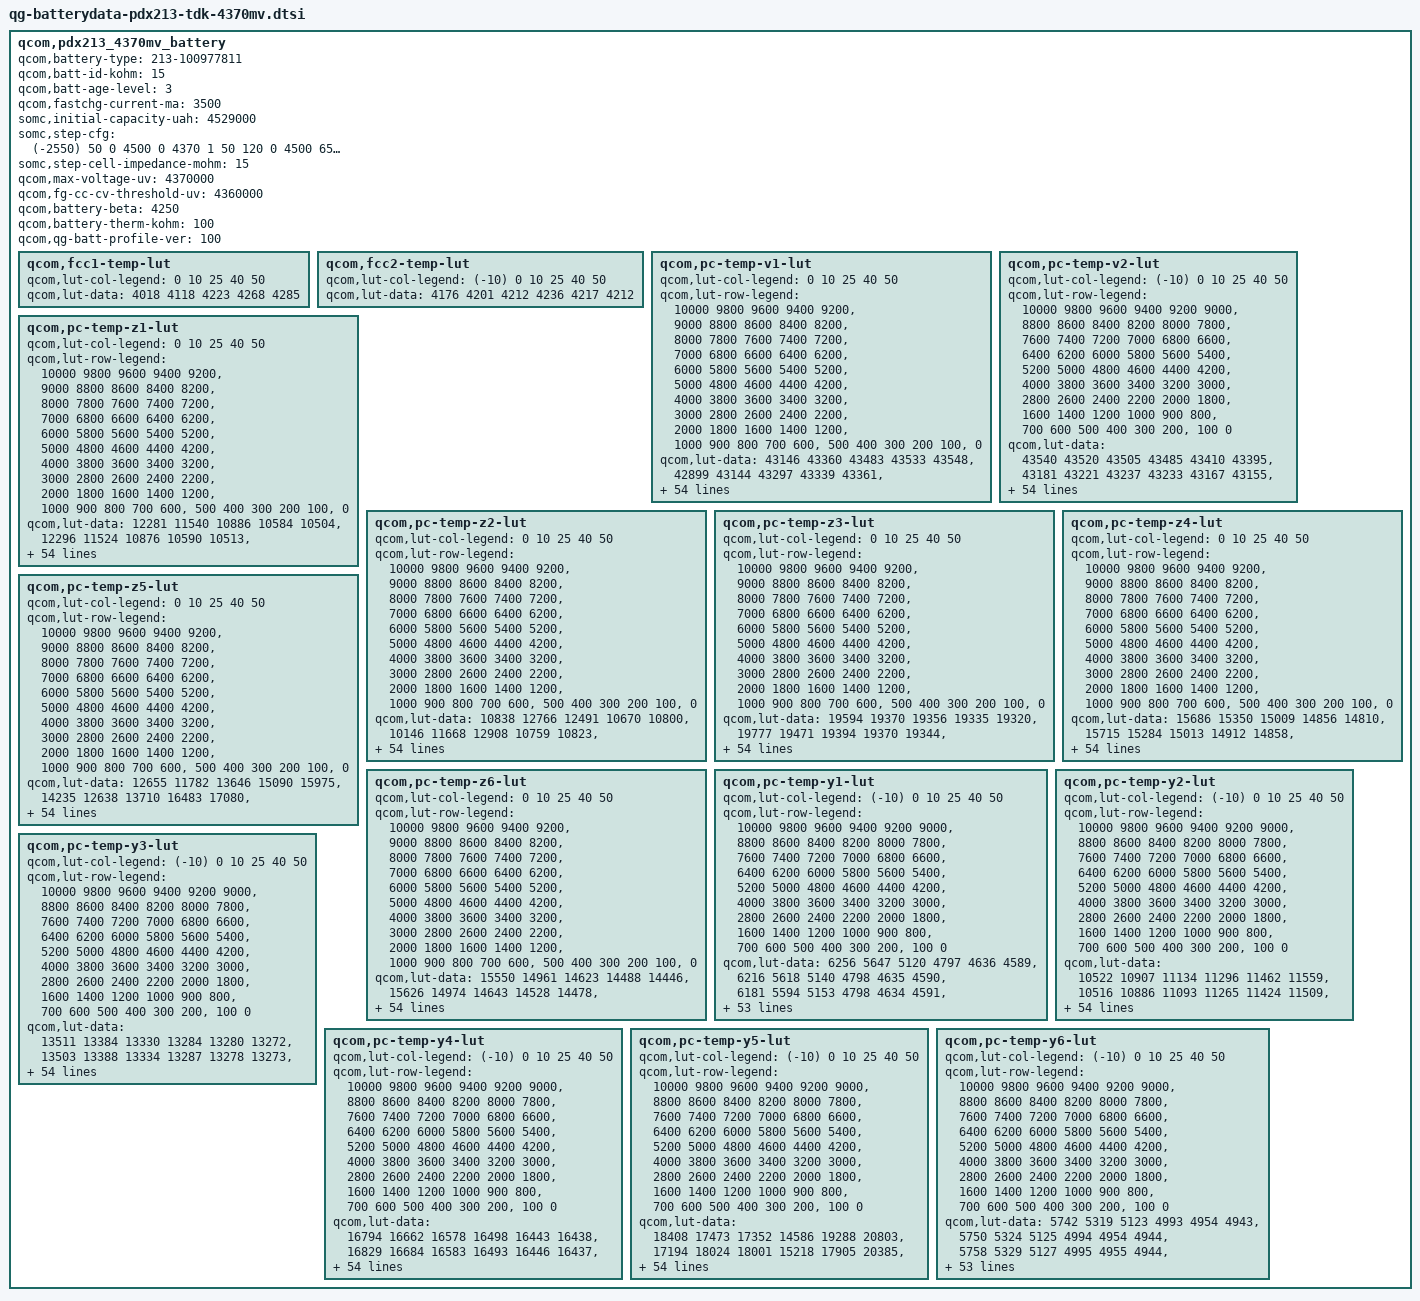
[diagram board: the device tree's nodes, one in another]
qcom,pdx213_4370mv_battery {
	/* Added or Modified by SOMC */
	qcom,battery-type = "213-100977811";
	qcom,batt-id-kohm = <15>;
	qcom,batt-age-level = <3>;
	qcom,fastchg-current-ma = <3500>;
	somc,initial-capacity-uah = <4529000>;
	somc,step-cfg = <
		(-2550) 50    0 4500    0 4370 1
		   50  120    0 4500  650 4370 2
		  120  150    0 4100 1950 4370 3
		  120  150 4100 4200 1500 4370 3
		  120  150 4200 4500  850 4370 3
		  150  200    0 4100 2150 4370 3
		  150  200 4100 4200 1750 4370 3
		  150  200 4200 4300 1500 4370 3
		  150  200 4300 4500 1050 4370 3
		  200  450    0 4150 3500 4370 3
		  200  450 4150 4200 2600 4370 3
		  200  450 4200 4300 1500 4370 3
		  200  450 4300 4500 1050 4370 3
		  450  550    0 4500 1300 4200 4
		  550 2550    0 4500    0 4200 5
	>;
	somc,step-cell-impedance-mohm = <15>;

	/* Prepared by Qualcomm */
    /* 4764144_SoMC_Licht_4221mAh_averaged_MasterSlave_Sept8th2020 */
    qcom,max-voltage-uv = <4370000>;
    qcom,fg-cc-cv-threshold-uv = <4360000>;
    /* qcom,fastchg-current-ma = <1500>; */
    /* qcom,batt-id-kohm = <0>; */
    qcom,battery-beta = <4250>;
    qcom,battery-therm-kohm = <100>;
    /* qcom,battery-type = "4764144_SoMC_Licht_4221mAh_averaged_MasterSlave_Sept8th2020"; */
    qcom,qg-batt-profile-ver = <100>;

	qcom,fcc1-temp-lut {
		qcom,lut-col-legend = <0 10 25 40 50>;
		qcom,lut-data = <4018 4118 4223 4268 4285>;
	};

	qcom,fcc2-temp-lut {
		qcom,lut-col-legend = <(-10) 0 10 25 40 50>;
		qcom,lut-data = <4176 4201 4212 4236 4217 4212>;
	};

	qcom,pc-temp-v1-lut {
		qcom,lut-col-legend = <0 10 25 40 50>;
		qcom,lut-row-legend = <10000 9800 9600 9400 9200>,
			<9000 8800 8600 8400 8200>,
			<8000 7800 7600 7400 7200>,
			<7000 6800 6600 6400 6200>,
			<6000 5800 5600 5400 5200>,
			<5000 4800 4600 4400 4200>,
			<4000 3800 3600 3400 3200>,
			<3000 2800 2600 2400 2200>,
			<2000 1800 1600 1400 1200>,
			<1000 900 800 700 600>,
			<500 400 300 200 100>,
			<0>;
		qcom,lut-data = <43146 43360 43483 43533 43548>,
			<42899 43144 43297 43339 43361>,
			<42681 42914 43072 43131 43156>,
			<42467 42674 42842 42917 42943>,
			<42248 42440 42607 42692 42724>,
			<42032 42216 42375 42459 42500>,
			<41821 41996 42153 42233 42274>,
			<41616 41782 41937 42011 42047>,
			<41416 41572 41719 41792 41823>,
			<41221 41366 41498 41573 41605>,
			<41032 41165 41281 41358 41390>,
			<40844 40968 41076 41147 41179>,
			<40657 40778 40879 40941 40971>,
			<40476 40595 40688 40743 40770>,
			<40305 40421 40503 40552 40578>,
			<40141 40262 40325 40368 40393>,
			<39991 40112 40158 40196 40218>,
			<39860 39957 39997 40034 40051>,
			<39734 39802 39834 39870 39885>,
			<39586 39633 39671 39699 39714>,
			<39416 39404 39493 39523 39540>,
			<39241 39126 39259 39322 39347>,
			<39058 38936 39017 39099 39129>,
			<38874 38836 38872 38925 38947>,
			<38748 38760 38783 38804 38816>,
			<38670 38690 38703 38702 38707>,
			<38610 38628 38615 38604 38606>,
			<38560 38566 38530 38513 38513>,
			<38517 38499 38454 38428 38427>,
			<38477 38432 38382 38349 38345>,
			<38434 38374 38319 38278 38269>,
			<38392 38323 38262 38215 38200>,
			<38353 38276 38210 38159 38138>,
			<38316 38232 38162 38105 38077>,
			<38280 38192 38120 38057 38022>,
			<38243 38152 38077 38008 37965>,
			<38206 38117 38036 37953 37898>,
			<38157 38075 37992 37894 37823>,
			<38075 38000 37926 37822 37743>,
			<37969 37890 37826 37732 37657>,
			<37855 37771 37711 37628 37560>,
			<37724 37643 37588 37509 37442>,
			<37578 37502 37450 37373 37305>,
			<37416 37338 37288 37217 37152>,
			<37286 37205 37154 37090 37029>,
			<37199 37126 37080 37019 36959>,
			<37174 37103 37060 37004 36941>,
			<37149 37084 37044 36988 36927>,
			<37120 37062 37028 36970 36912>,
			<37069 37020 36985 36922 36857>,
			<36888 36823 36756 36668 36581>,
			<36450 36393 36330 36239 36152>,
			<35886 35834 35773 35682 35596>,
			<35115 35067 35019 34928 34842>,
			<33823 33820 33856 33774 33698>,
			<30000 30000 30000 30000 30000>;
	};

	qcom,pc-temp-v2-lut {
		qcom,lut-col-legend = <(-10) 0 10 25 40 50>;
		qcom,lut-row-legend = <10000 9800 9600 9400 9200 9000>,
			<8800 8600 8400 8200 8000 7800>,
			<7600 7400 7200 7000 6800 6600>,
			<6400 6200 6000 5800 5600 5400>,
			<5200 5000 4800 4600 4400 4200>,
			<4000 3800 3600 3400 3200 3000>,
			<2800 2600 2400 2200 2000 1800>,
			<1600 1400 1200 1000 900 800>,
			<700 600 500 400 300 200>,
			<100 0>;
		qcom,lut-data = <43540 43520 43505 43485 43410 43395>,
			<43181 43221 43237 43233 43167 43155>,
			<42856 42940 42980 42989 42930 42921>,
			<42568 42681 42736 42754 42699 42691>,
			<42312 42441 42505 42527 42474 42468>,
			<42079 42208 42277 42303 42251 42246>,
			<41868 41976 42049 42077 42029 42023>,
			<41670 41746 41823 41853 41809 41802>,
			<41461 41522 41602 41632 41593 41586>,
			<41238 41299 41384 41415 41378 41373>,
			<41021 41088 41173 41203 41168 41164>,
			<40832 40904 40970 40996 40963 40960>,
			<40650 40731 40773 40795 40763 40762>,
			<40428 40548 40584 40600 40572 40570>,
			<40135 40355 40404 40410 40386 40384>,
			<39851 40154 40221 40228 40208 40204>,
			<39634 39940 40033 40060 40041 40036>,
			<39445 39718 39838 39894 39878 39874>,
			<39245 39498 39625 39711 39701 39699>,
			<39027 39273 39382 39514 39511 39515>,
			<38817 39064 39159 39311 39317 39325>,
			<38628 38884 38978 39089 39103 39114>,
			<38455 38722 38819 38878 38895 38906>,
			<38335 38577 38679 38726 38742 38753>,
			<38254 38450 38557 38610 38627 38639>,
			<38188 38329 38446 38505 38526 38538>,
			<38129 38204 38345 38406 38430 38441>,
			<38076 38086 38251 38315 38342 38350>,
			<38024 38009 38163 38230 38260 38267>,
			<37973 37958 38080 38149 38185 38190>,
			<37922 37917 38002 38077 38116 38119>,
			<37871 37880 37925 38011 38053 38055>,
			<37820 37848 37854 37952 37995 37994>,
			<37766 37815 37804 37896 37928 37922>,
			<37711 37785 37771 37845 37853 37832>,
			<37653 37750 37737 37787 37772 37736>,
			<37586 37703 37700 37714 37683 37639>,
			<37511 37639 37660 37633 37590 37539>,
			<37429 37562 37604 37555 37502 37448>,
			<37339 37465 37523 37478 37422 37368>,
			<37244 37353 37424 37390 37334 37281>,
			<37149 37224 37304 37281 37226 37172>,
			<37056 37078 37164 37154 37105 37050>,
			<36968 36934 37005 37000 36963 36909>,
			<36882 36817 36878 36908 36883 36830>,
			<36785 36740 36813 36874 36855 36804>,
			<36735 36702 36782 36858 36842 36792>,
			<36677 36668 36749 36838 36821 36775>,
			<36606 36617 36694 36804 36794 36750>,
			<36512 36517 36595 36710 36709 36642>,
			<36346 36289 36341 36417 36393 36311>,
			<36017 35835 35868 35920 35908 35826>,
			<35454 35158 35218 35283 35277 35197>,
			<34570 34172 34323 34397 34418 34332>,
			<33307 32671 32925 33187 33215 33180>,
			<31462 29587 29752 29598 29684 29844>;
	};

	qcom,pc-temp-z1-lut {
		qcom,lut-col-legend = <0 10 25 40 50>;
		qcom,lut-row-legend = <10000 9800 9600 9400 9200>,
			<9000 8800 8600 8400 8200>,
			<8000 7800 7600 7400 7200>,
			<7000 6800 6600 6400 6200>,
			<6000 5800 5600 5400 5200>,
			<5000 4800 4600 4400 4200>,
			<4000 3800 3600 3400 3200>,
			<3000 2800 2600 2400 2200>,
			<2000 1800 1600 1400 1200>,
			<1000 900 800 700 600>,
			<500 400 300 200 100>,
			<0>;
		qcom,lut-data = <12281 11540 10886 10584 10504>,
			<12296 11524 10876 10590 10513>,
			<12287 11511 10871 10591 10513>,
			<12275 11490 10866 10592 10513>,
			<12257 11472 10861 10590 10513>,
			<12237 11452 10856 10588 10514>,
			<12222 11436 10851 10586 10514>,
			<12206 11435 10847 10585 10513>,
			<12190 11443 10846 10584 10511>,
			<12171 11448 10845 10584 10512>,
			<12149 11439 10845 10583 10513>,
			<12138 11425 10845 10583 10513>,
			<12137 11420 10846 10583 10513>,
			<12141 11418 10846 10583 10512>,
			<12144 11418 10847 10583 10513>,
			<12140 11423 10848 10584 10513>,
			<12136 11434 10849 10584 10513>,
			<12143 11440 10851 10586 10515>,
			<12158 11442 10853 10589 10517>,
			<12173 11443 10856 10590 10518>,
			<12197 11443 10859 10591 10519>,
			<12211 11441 10862 10594 10521>,
			<12210 11441 10865 10597 10525>,
			<12207 11449 10869 10600 10528>,
			<12205 11460 10874 10604 10530>,
			<12207 11465 10880 10607 10532>,
			<12210 11472 10885 10610 10534>,
			<12209 11475 10891 10613 10536>,
			<12207 11476 10895 10615 10538>,
			<12206 11477 10897 10618 10540>,
			<12206 11482 10900 10620 10542>,
			<12207 11492 10904 10622 10544>,
			<12209 11500 10909 10625 10546>,
			<12218 11500 10913 10627 10548>,
			<12228 11499 10914 10630 10549>,
			<12234 11502 10917 10634 10551>,
			<12239 11509 10923 10637 10553>,
			<12244 11517 10931 10640 10556>,
			<12267 11525 10938 10643 10558>,
			<12296 11535 10942 10644 10561>,
			<12308 11539 10948 10646 10562>,
			<12313 11555 10956 10649 10564>,
			<12314 11565 10963 10652 10566>,
			<12308 11569 10967 10655 10567>,
			<12331 11567 10974 10658 10569>,
			<12329 11566 10975 10660 10571>,
			<12323 11572 10977 10658 10570>,
			<12323 11573 10981 10661 10571>,
			<12339 11572 10984 10663 10572>,
			<12368 11593 10993 10666 10574>,
			<12380 11594 10994 10674 10580>,
			<12372 11614 11015 10683 10589>,
			<12434 11642 11036 10698 10602>,
			<12452 11692 11064 10723 10621>,
			<12452 11692 11064 10723 10621>,
			<12452 11692 11064 10723 10621>;
	};

	qcom,pc-temp-z2-lut {
		qcom,lut-col-legend = <0 10 25 40 50>;
		qcom,lut-row-legend = <10000 9800 9600 9400 9200>,
			<9000 8800 8600 8400 8200>,
			<8000 7800 7600 7400 7200>,
			<7000 6800 6600 6400 6200>,
			<6000 5800 5600 5400 5200>,
			<5000 4800 4600 4400 4200>,
			<4000 3800 3600 3400 3200>,
			<3000 2800 2600 2400 2200>,
			<2000 1800 1600 1400 1200>,
			<1000 900 800 700 600>,
			<500 400 300 200 100>,
			<0>;
		qcom,lut-data = <10838 12766 12491 10670 10800>,
			<10146 11668 12908 10759 10823>,
			<10112 10981 11894 11535 11254>,
			<10092 10458 11206 12039 11651>,
			<10072 10252 10688 11608 11619>,
			<10058 10232 10444 10865 11514>,
			<10052 10222 10599 10799 11485>,
			<10048 10226 10862 11346 11506>,
			<10047 10253 10935 11729 11520>,
			<10050 10279 10895 11738 11479>,
			<10057 10292 10848 11717 11409>,
			<10068 10304 10895 11703 11399>,
			<10088 10330 11023 11683 11454>,
			<10110 10474 11098 11688 11496>,
			<10130 10604 11153 11750 11244>,
			<10151 10665 11180 11817 10820>,
			<10167 10745 10984 11656 10745>,
			<10176 10727 10657 10992 10774>,
			<10184 10554 10586 10645 10795>,
			<10196 10400 10592 10701 10801>,
			<10212 10390 10595 10768 10808>,
			<10231 10392 10578 10755 10824>,
			<10252 10393 10548 10689 10861>,
			<10274 10392 10549 10667 10887>,
			<10286 10391 10603 10798 10890>,
			<10292 10395 10649 10939 10878>,
			<10296 10411 10655 10900 10823>,
			<10296 10421 10649 10759 10704>,
			<10296 10421 10631 10688 10646>,
			<10297 10421 10585 10670 10642>,
			<10304 10423 10557 10662 10640>,
			<10312 10431 10569 10673 10647>,
			<10317 10441 10595 10704 10679>,
			<10319 10456 10621 10720 10718>,
			<10321 10474 10652 10721 10796>,
			<10325 10484 10682 10725 10888>,
			<10333 10488 10705 10793 10955>,
			<10340 10492 10725 10939 11014>,
			<10349 10508 10751 11021 11067>,
			<10356 10535 10791 11064 11134>,
			<10355 10544 10814 11089 11177>,
			<10346 10530 10810 11057 11170>,
			<10345 10522 10805 11008 11142>,
			<10361 10529 10812 11047 11031>,
			<10537 10627 10845 11038 11010>,
			<10546 10663 10863 10943 11069>,
			<10420 10682 10813 10959 11029>,
			<10160 10736 10762 10914 10998>,
			<9992 10816 10753 10924 11091>,
			<9936 10843 10767 11042 11209>,
			<9749 10825 11020 10862 10765>,
			<9823 10893 10956 10714 10608>,
			<9709 10795 10922 10675 10599>,
			<9594 10649 10817 10542 10518>,
			<9594 10649 10817 10542 10518>,
			<9594 10649 10817 10542 10518>;
	};

	qcom,pc-temp-z3-lut {
		qcom,lut-col-legend = <0 10 25 40 50>;
		qcom,lut-row-legend = <10000 9800 9600 9400 9200>,
			<9000 8800 8600 8400 8200>,
			<8000 7800 7600 7400 7200>,
			<7000 6800 6600 6400 6200>,
			<6000 5800 5600 5400 5200>,
			<5000 4800 4600 4400 4200>,
			<4000 3800 3600 3400 3200>,
			<3000 2800 2600 2400 2200>,
			<2000 1800 1600 1400 1200>,
			<1000 900 800 700 600>,
			<500 400 300 200 100>,
			<0>;
		qcom,lut-data = <19594 19370 19356 19335 19320>,
			<19777 19471 19394 19370 19344>,
			<19811 19545 19458 19406 19370>,
			<19829 19606 19480 19424 19386>,
			<19844 19632 19484 19418 19385>,
			<19852 19636 19488 19408 19382>,
			<19853 19638 19500 19406 19379>,
			<19849 19634 19515 19412 19377>,
			<19844 19614 19517 19416 19374>,
			<19831 19597 19490 19407 19368>,
			<19815 19591 19464 19394 19361>,
			<19808 19587 19462 19391 19357>,
			<19807 19586 19464 19392 19356>,
			<19806 19589 19464 19392 19355>,
			<19793 19593 19461 19390 19345>,
			<19763 19592 19456 19387 19330>,
			<19745 19589 19441 19378 19326>,
			<19741 19584 19421 19353 19326>,
			<19739 19570 19418 19340 19326>,
			<19740 19559 19424 19347 19327>,
			<19752 19565 19429 19356 19329>,
			<19763 19585 19430 19354 19330>,
			<19768 19594 19429 19342 19329>,
			<19772 19582 19425 19337 19330>,
			<19773 19568 19414 19364 19354>,
			<19768 19565 19407 19395 19384>,
			<19760 19564 19425 19398 19385>,
			<19753 19563 19454 19398 19373>,
			<19745 19571 19460 19397 19363>,
			<19740 19583 19459 19392 19358>,
			<19736 19585 19458 19385 19353>,
			<19734 19580 19453 19378 19348>,
			<19731 19574 19444 19369 19341>,
			<19727 19570 19437 19362 19336>,
			<19723 19564 19431 19354 19329>,
			<19718 19559 19426 19349 19324>,
			<19713 19554 19423 19350 19325>,
			<19708 19550 19420 19353 19326>,
			<19702 19545 19417 19353 19327>,
			<19695 19540 19413 19350 19328>,
			<19688 19535 19408 19347 19328>,
			<19680 19530 19404 19345 19328>,
			<19668 19523 19401 19344 19327>,
			<19645 19513 19399 19348 19331>,
			<19549 19483 19393 19345 19327>,
			<19486 19466 19381 19335 19317>,
			<19397 19451 19377 19325 19317>,
			<19318 19424 19375 19327 19315>,
			<19299 19385 19366 19323 19304>,
			<19291 19386 19360 19319 19302>,
			<19273 19410 19341 19339 19335>,
			<19303 19363 19349 19354 19343>,
			<19303 19330 19342 19356 19342>,
			<19314 19334 19350 19359 19346>,
			<19314 19334 19350 19359 19346>,
			<19314 19334 19350 19359 19346>;
	};

	qcom,pc-temp-z4-lut {
		qcom,lut-col-legend = <0 10 25 40 50>;
		qcom,lut-row-legend = <10000 9800 9600 9400 9200>,
			<9000 8800 8600 8400 8200>,
			<8000 7800 7600 7400 7200>,
			<7000 6800 6600 6400 6200>,
			<6000 5800 5600 5400 5200>,
			<5000 4800 4600 4400 4200>,
			<4000 3800 3600 3400 3200>,
			<3000 2800 2600 2400 2200>,
			<2000 1800 1600 1400 1200>,
			<1000 900 800 700 600>,
			<500 400 300 200 100>,
			<0>;
		qcom,lut-data = <15686 15350 15009 14856 14810>,
			<15715 15284 15013 14912 14858>,
			<15564 15205 14949 14850 14822>,
			<15424 15117 14902 14793 14776>,
			<15320 15041 14869 14777 14750>,
			<15231 14978 14835 14767 14730>,
			<15158 14926 14780 14749 14718>,
			<15097 14894 14721 14718 14710>,
			<15047 14872 14702 14697 14704>,
			<15005 14856 14719 14694 14698>,
			<14970 14843 14736 14691 14693>,
			<14944 14834 14726 14685 14686>,
			<14921 14827 14705 14670 14675>,
			<14908 14814 14693 14657 14667>,
			<14917 14802 14686 14648 14669>,
			<14939 14785 14683 14641 14675>,
			<14948 14759 14693 14644 14673>,
			<14919 14753 14712 14663 14663>,
			<14881 14767 14724 14681 14658>,
			<14875 14795 14732 14691 14666>,
			<14892 14861 14744 14702 14686>,
			<14918 14982 14820 14746 14720>,
			<14975 15034 14930 14841 14788>,
			<15053 15027 14951 14881 14823>,
			<15080 15014 14938 14841 14787>,
			<15074 14993 14917 14787 14736>,
			<15062 14958 14878 14760 14721>,
			<15046 14925 14828 14741 14715>,
			<15022 14899 14799 14728 14708>,
			<15000 14876 14780 14717 14699>,
			<14981 14863 14769 14709 14690>,
			<14965 14855 14764 14703 14683>,
			<14951 14850 14760 14698 14677>,
			<14939 14847 14760 14697 14675>,
			<14927 14845 14760 14701 14678>,
			<14916 14841 14761 14706 14684>,
			<14904 14833 14762 14713 14696>,
			<14895 14827 14764 14721 14715>,
			<14889 14826 14768 14728 14721>,
			<14882 14826 14778 14736 14717>,
			<14871 14825 14784 14740 14712>,
			<14850 14808 14776 14735 14708>,
			<14828 14788 14763 14728 14705>,
			<14808 14773 14757 14727 14705>,
			<14782 14733 14734 14720 14703>,
			<14817 14706 14704 14699 14688>,
			<14907 14707 14689 14689 14673>,
			<14984 14721 14672 14665 14653>,
			<14998 14755 14664 14648 14642>,
			<15000 14749 14671 14655 14648>,
			<15018 14734 14723 14669 14646>,
			<15006 14795 14717 14656 14643>,
			<15013 14837 14725 14655 14645>,
			<15023 14841 14717 14653 14642>,
			<15023 14841 14717 14653 14642>,
			<15023 14841 14717 14653 14642>;
	};

	qcom,pc-temp-z5-lut {
		qcom,lut-col-legend = <0 10 25 40 50>;
		qcom,lut-row-legend = <10000 9800 9600 9400 9200>,
			<9000 8800 8600 8400 8200>,
			<8000 7800 7600 7400 7200>,
			<7000 6800 6600 6400 6200>,
			<6000 5800 5600 5400 5200>,
			<5000 4800 4600 4400 4200>,
			<4000 3800 3600 3400 3200>,
			<3000 2800 2600 2400 2200>,
			<2000 1800 1600 1400 1200>,
			<1000 900 800 700 600>,
			<500 400 300 200 100>,
			<0>;
		qcom,lut-data = <12655 11782 13646 15090 15975>,
			<14235 12638 13710 16483 17080>,
			<14677 13882 15190 17946 18630>,
			<15136 15515 16424 19099 19926>,
			<15751 16887 17386 19752 20850>,
			<16409 17942 18571 20286 21587>,
			<17080 18775 20892 21210 22255>,
			<17774 19206 23924 23109 22995>,
			<18425 19436 25132 24266 23427>,
			<18939 19696 23662 23705 23201>,
			<19460 20110 22004 22875 22684>,
			<20489 20643 22353 23168 22759>,
			<22931 21341 23652 25423 24539>,
			<24861 22474 24671 27935 25894>,
			<24029 23253 25669 30569 24146>,
			<21472 23200 26197 32753 21134>,
			<20229 22997 25055 31248 20766>,
			<20814 23072 23134 24102 22506>,
			<22140 24372 23084 20365 23950>,
			<24661 26418 25421 22841 24379>,
			<30293 29425 27111 25920 24636>,
			<34644 33796 26288 24529 23538>,
			<35776 35446 24246 18585 18234>,
			<36429 31099 22067 15846 15208>,
			<36470 25433 18905 16635 17402>,
			<34456 23565 17140 17925 20306>,
			<31710 22641 18105 19026 20595>,
			<30077 22320 20280 20157 20288>,
			<28797 23985 22397 21413 20163>,
			<28247 26886 24728 22968 21066>,
			<28429 28713 26800 24425 22469>,
			<28847 30028 28483 25589 23672>,
			<29247 30984 29864 26660 24976>,
			<29660 31675 30574 27017 25473>,
			<30054 32201 31049 26916 25469>,
			<30376 32271 31248 26819 25388>,
			<30669 31831 30878 26986 24967>,
			<30914 31292 29997 27276 23932>,
			<31212 30977 28788 27092 22996>,
			<31464 30719 26744 24357 22126>,
			<31346 30373 25098 21727 21468>,
			<30417 29849 24347 21176 21072>,
			<29339 29139 23805 20999 20736>,
			<27951 27917 23171 20822 20661>,
			<22479 28233 23782 20239 19560>,
			<17962 26848 24177 19995 18171>,
			<14276 23119 24134 18969 19446>,
			<11855 18321 25247 21910 22501>,
			<11642 15937 23057 24795 22284>,
			<11557 16164 21215 21652 19630>,
			<11426 17082 15516 19608 25097>,
			<11644 13953 15564 23039 27381>,
			<11561 12619 14712 22886 25323>,
			<11789 12803 14954 23090 26565>,
			<11789 12803 14954 23090 26565>,
			<11789 12803 14954 23090 26565>;
	};

	qcom,pc-temp-z6-lut {
		qcom,lut-col-legend = <0 10 25 40 50>;
		qcom,lut-row-legend = <10000 9800 9600 9400 9200>,
			<9000 8800 8600 8400 8200>,
			<8000 7800 7600 7400 7200>,
			<7000 6800 6600 6400 6200>,
			<6000 5800 5600 5400 5200>,
			<5000 4800 4600 4400 4200>,
			<4000 3800 3600 3400 3200>,
			<3000 2800 2600 2400 2200>,
			<2000 1800 1600 1400 1200>,
			<1000 900 800 700 600>,
			<500 400 300 200 100>,
			<0>;
		qcom,lut-data = <15550 14961 14623 14488 14446>,
			<15626 14974 14643 14528 14478>,
			<15562 14970 14646 14522 14475>,
			<15500 14952 14644 14513 14470>,
			<15449 14929 14629 14503 14462>,
			<15402 14903 14610 14491 14450>,
			<15360 14874 14593 14482 14442>,
			<15321 14850 14575 14473 14437>,
			<15285 14828 14565 14466 14433>,
			<15251 14812 14559 14458 14427>,
			<15220 14802 14553 14452 14421>,
			<15201 14795 14546 14445 14415>,
			<15190 14791 14539 14439 14410>,
			<15182 14788 14534 14434 14406>,
			<15176 14784 14529 14429 14400>,
			<15172 14775 14526 14425 14395>,
			<15166 14763 14523 14420 14391>,
			<15152 14759 14520 14416 14387>,
			<15138 14762 14521 14414 14385>,
			<15138 14767 14527 14420 14389>,
			<15154 14796 14538 14432 14399>,
			<15176 14861 14573 14453 14416>,
			<15207 14890 14620 14488 14446>,
			<15244 14883 14628 14503 14462>,
			<15257 14872 14618 14500 14459>,
			<15253 14860 14607 14494 14454>,
			<15246 14846 14600 14487 14448>,
			<15237 14835 14594 14479 14440>,
			<15225 14831 14587 14471 14432>,
			<15214 14828 14580 14464 14426>,
			<15207 14825 14573 14457 14419>,
			<15201 14820 14568 14451 14413>,
			<15196 14817 14563 14444 14407>,
			<15192 14815 14559 14440 14403>,
			<15188 14813 14557 14438 14401>,
			<15186 14811 14555 14438 14401>,
			<15183 14807 14556 14440 14405>,
			<15183 14805 14556 14446 14415>,
			<15186 14806 14557 14449 14418>,
			<15190 14807 14560 14451 14417>,
			<15190 14808 14562 14452 14415>,
			<15185 14802 14558 14449 14414>,
			<15180 14795 14551 14446 14412>,
			<15173 14789 14550 14448 14414>,
			<15133 14766 14539 14444 14412>,
			<15121 14749 14521 14430 14400>,
			<15115 14743 14512 14420 14394>,
			<15112 14738 14504 14410 14384>,
			<15113 14735 14497 14402 14373>,
			<15119 14738 14499 14403 14375>,
			<15134 14751 14515 14421 14393>,
			<15156 14762 14520 14426 14398>,
			<15180 14774 14525 14429 14401>,
			<15223 14798 14534 14434 14406>,
			<15223 14798 14534 14434 14406>,
			<15223 14798 14534 14434 14406>;
	};

	qcom,pc-temp-y1-lut {
		qcom,lut-col-legend = <(-10) 0 10 25 40 50>;
		qcom,lut-row-legend = <10000 9800 9600 9400 9200 9000>,
			<8800 8600 8400 8200 8000 7800>,
			<7600 7400 7200 7000 6800 6600>,
			<6400 6200 6000 5800 5600 5400>,
			<5200 5000 4800 4600 4400 4200>,
			<4000 3800 3600 3400 3200 3000>,
			<2800 2600 2400 2200 2000 1800>,
			<1600 1400 1200 1000 900 800>,
			<700 600 500 400 300 200>,
			<100 0>;
		qcom,lut-data = <6256 5647 5120 4797 4636 4589>,
			<6216 5618 5140 4798 4635 4590>,
			<6181 5594 5153 4798 4634 4591>,
			<6152 5577 5160 4797 4634 4591>,
			<6133 5567 5162 4796 4633 4592>,
			<6126 5563 5161 4795 4633 4592>,
			<6136 5570 5153 4792 4633 4591>,
			<6154 5581 5141 4789 4633 4591>,
			<6164 5580 5140 4787 4633 4591>,
			<6180 5563 5147 4786 4632 4591>,
			<6191 5550 5151 4785 4632 4591>,
			<6185 5544 5143 4784 4632 4591>,
			<6171 5537 5129 4783 4632 4591>,
			<6163 5536 5127 4783 4632 4591>,
			<6144 5540 5133 4785 4633 4591>,
			<6129 5546 5136 4786 4633 4592>,
			<6135 5557 5135 4786 4633 4593>,
			<6150 5572 5133 4786 4633 4594>,
			<6155 5574 5134 4787 4634 4594>,
			<6141 5561 5137 4787 4635 4594>,
			<6127 5551 5140 4788 4637 4593>,
			<6138 5564 5144 4791 4637 4594>,
			<6162 5588 5150 4795 4638 4595>,
			<6170 5593 5150 4798 4639 4597>,
			<6166 5580 5144 4801 4640 4598>,
			<6167 5568 5139 4804 4642 4599>,
			<6180 5571 5145 4806 4644 4600>,
			<6200 5580 5155 4808 4648 4601>,
			<6207 5581 5160 4811 4649 4601>,
			<6184 5579 5162 4815 4650 4603>,
			<6155 5576 5163 4818 4651 4604>,
			<6144 5568 5163 4821 4652 4605>,
			<6143 5559 5163 4823 4653 4607>,
			<6147 5557 5166 4825 4655 4609>,
			<6149 5562 5175 4828 4657 4610>,
			<6147 5566 5180 4831 4659 4611>,
			<6144 5563 5179 4833 4659 4612>,
			<6145 5558 5176 4835 4659 4613>,
			<6150 5557 5175 4838 4659 4614>,
			<6147 5557 5174 4842 4661 4614>,
			<6137 5558 5175 4846 4663 4615>,
			<6130 5569 5183 4849 4665 4615>,
			<6122 5583 5195 4851 4666 4616>,
			<6136 5594 5206 4853 4668 4617>,
			<6152 5594 5205 4859 4670 4618>,
			<6151 5577 5195 4860 4671 4620>,
			<6214 5591 5198 4863 4672 4620>,
			<6283 5589 5198 4870 4673 4620>,
			<6290 5619 5199 4869 4674 4622>,
			<6338 5634 5211 4871 4674 4621>,
			<6369 5652 5212 4875 4675 4622>,
			<6406 5670 5239 4883 4679 4626>,
			<6474 5735 5255 4897 4684 4631>,
			<6738 5870 5284 4918 4694 4640>,
			<6738 5870 5284 4918 4694 4640>,
			<6738 5870 5284 4918 4694 4640>;
	};

	qcom,pc-temp-y2-lut {
		qcom,lut-col-legend = <(-10) 0 10 25 40 50>;
		qcom,lut-row-legend = <10000 9800 9600 9400 9200 9000>,
			<8800 8600 8400 8200 8000 7800>,
			<7600 7400 7200 7000 6800 6600>,
			<6400 6200 6000 5800 5600 5400>,
			<5200 5000 4800 4600 4400 4200>,
			<4000 3800 3600 3400 3200 3000>,
			<2800 2600 2400 2200 2000 1800>,
			<1600 1400 1200 1000 900 800>,
			<700 600 500 400 300 200>,
			<100 0>;
		qcom,lut-data = <10522 10907 11134 11296 11462 11559>,
			<10516 10886 11093 11265 11424 11509>,
			<10519 10857 11053 11234 11347 11434>,
			<10530 10826 11015 11205 11258 11351>,
			<10545 10800 10980 11177 11185 11281>,
			<10564 10786 10947 11153 11154 11243>,
			<10597 10781 10912 11128 11156 11228>,
			<10641 10778 10883 11108 11159 11217>,
			<10669 10777 10879 11101 11162 11214>,
			<10706 10779 10885 11099 11164 11220>,
			<10731 10783 10896 11098 11167 11230>,
			<10724 10822 10915 11107 11191 11253>,
			<10708 10892 10944 11125 11232 11284>,
			<10716 10934 10977 11147 11262 11296>,
			<10774 10961 11017 11183 11285 11301>,
			<10829 10984 11062 11228 11316 11310>,
			<10849 11009 11123 11301 11374 11358>,
			<10862 11037 11181 11373 11456 11450>,
			<10848 11049 11191 11391 11543 11568>,
			<10593 11054 11187 11397 11652 11759>,
			<10313 11060 11184 11398 11709 11872>,
			<10123 11072 11195 11386 11633 11820>,
			<9824 11086 11218 11368 11512 11723>,
			<9717 11088 11236 11375 11490 11678>,
			<9700 11073 11252 11419 11515 11657>,
			<9691 11061 11267 11450 11550 11653>,
			<9687 11083 11284 11458 11596 11706>,
			<9684 11127 11300 11465 11657 11800>,
			<9681 11137 11302 11478 11712 11834>,
			<9678 11105 11292 11502 11772 11849>,
			<9675 11062 11284 11530 11835 11875>,
			<9673 11023 11283 11571 11918 12031>,
			<9671 10980 11284 11607 11994 12261>,
			<9669 10935 11279 11610 12000 12285>,
			<9668 10892 11260 11606 11959 12114>,
			<9667 10839 11235 11599 11903 11985>,
			<9666 10676 11209 11566 11822 11968>,
			<9665 10365 11177 11527 11737 11957>,
			<9664 10175 11141 11519 11701 11927>,
			<9663 9904 11099 11517 11671 11835>,
			<9663 9703 11047 11514 11653 11769>,
			<9662 9687 10967 11492 11681 11780>,
			<9661 9679 10863 11449 11719 11795>,
			<9660 9673 10760 11348 11657 11784>,
			<9659 9669 10569 11262 11529 11655>,
			<9657 9666 10534 11304 11463 11539>,
			<9656 9664 10372 11313 11441 11383>,
			<9655 9662 10237 11290 11377 11372>,
			<9653 9660 9920 11274 11400 11419>,
			<9651 9658 9787 11255 11478 11455>,
			<9650 9655 9710 11198 11439 11327>,
			<9649 9651 9678 11127 11294 11256>,
			<9648 9650 9663 11020 11175 11160>,
			<9648 9650 9655 10913 11124 11021>,
			<9648 9650 9655 10913 11124 11021>,
			<9648 9650 9655 10913 11124 11021>;
	};

	qcom,pc-temp-y3-lut {
		qcom,lut-col-legend = <(-10) 0 10 25 40 50>;
		qcom,lut-row-legend = <10000 9800 9600 9400 9200 9000>,
			<8800 8600 8400 8200 8000 7800>,
			<7600 7400 7200 7000 6800 6600>,
			<6400 6200 6000 5800 5600 5400>,
			<5200 5000 4800 4600 4400 4200>,
			<4000 3800 3600 3400 3200 3000>,
			<2800 2600 2400 2200 2000 1800>,
			<1600 1400 1200 1000 900 800>,
			<700 600 500 400 300 200>,
			<100 0>;
		qcom,lut-data = <13511 13384 13330 13284 13280 13272>,
			<13503 13388 13334 13287 13278 13273>,
			<13501 13394 13337 13291 13277 13273>,
			<13503 13399 13341 13294 13277 13274>,
			<13509 13404 13344 13297 13278 13275>,
			<13517 13407 13347 13299 13280 13276>,
			<13531 13408 13349 13300 13282 13276>,
			<13547 13410 13351 13301 13286 13277>,
			<13545 13412 13352 13302 13287 13278>,
			<13503 13416 13353 13303 13288 13280>,
			<13471 13418 13353 13303 13289 13282>,
			<13475 13409 13352 13305 13289 13283>,
			<13485 13395 13349 13307 13289 13285>,
			<13487 13393 13348 13307 13290 13285>,
			<13475 13400 13348 13307 13293 13285>,
			<13462 13406 13347 13306 13295 13285>,
			<13454 13402 13347 13305 13295 13286>,
			<13447 13392 13347 13304 13295 13287>,
			<13439 13384 13346 13303 13295 13287>,
			<13428 13377 13339 13304 13292 13286>,
			<13419 13371 13332 13303 13288 13284>,
			<13409 13366 13329 13299 13284 13280>,
			<13400 13363 13326 13293 13280 13274>,
			<13397 13359 13324 13292 13278 13273>,
			<13401 13357 13323 13292 13278 13274>,
			<13407 13354 13322 13292 13278 13274>,
			<13417 13342 13321 13292 13277 13274>,
			<13436 13324 13321 13292 13277 13274>,
			<13456 13320 13320 13292 13277 13273>,
			<13478 13322 13319 13292 13277 13273>,
			<13505 13327 13318 13292 13278 13273>,
			<13535 13333 13317 13292 13279 13274>,
			<13571 13342 13315 13292 13281 13275>,
			<13612 13350 13316 13292 13281 13275>,
			<13659 13357 13318 13293 13280 13274>,
			<13711 13363 13321 13293 13279 13274>,
			<13766 13371 13324 13293 13278 13273>,
			<13824 13379 13327 13292 13277 13272>,
			<13885 13390 13330 13291 13276 13272>,
			<13948 13409 13332 13291 13276 13273>,
			<14015 13434 13334 13291 13276 13273>,
			<14086 13461 13334 13292 13276 13274>,
			<14164 13496 13335 13292 13277 13275>,
			<14250 13542 13338 13292 13276 13272>,
			<14360 13616 13341 13294 13277 13272>,
			<14582 13691 13345 13295 13281 13277>,
			<14642 13733 13346 13299 13283 13281>,
			<14937 13841 13354 13303 13284 13284>,
			<15447 13979 13366 13310 13291 13286>,
			<16346 14178 13397 13313 13292 13284>,
			<18104 14623 13442 13309 13287 13281>,
			<22165 15812 13531 13311 13287 13282>,
			<34274 19322 13771 13318 13288 13283>,
			<65535 32012 14685 13327 13292 13286>,
			<65535 32012 14685 13327 13292 13286>,
			<65535 32012 14685 13327 13292 13286>;
	};

	qcom,pc-temp-y4-lut {
		qcom,lut-col-legend = <(-10) 0 10 25 40 50>;
		qcom,lut-row-legend = <10000 9800 9600 9400 9200 9000>,
			<8800 8600 8400 8200 8000 7800>,
			<7600 7400 7200 7000 6800 6600>,
			<6400 6200 6000 5800 5600 5400>,
			<5200 5000 4800 4600 4400 4200>,
			<4000 3800 3600 3400 3200 3000>,
			<2800 2600 2400 2200 2000 1800>,
			<1600 1400 1200 1000 900 800>,
			<700 600 500 400 300 200>,
			<100 0>;
		qcom,lut-data = <16794 16662 16578 16498 16443 16438>,
			<16829 16684 16583 16493 16446 16437>,
			<16879 16708 16588 16489 16448 16437>,
			<16934 16732 16593 16486 16450 16438>,
			<16979 16751 16598 16484 16451 16439>,
			<17003 16764 16601 16484 16452 16440>,
			<17008 16772 16602 16486 16451 16442>,
			<17010 16777 16604 16490 16450 16444>,
			<17030 16778 16607 16494 16450 16446>,
			<17127 16779 16615 16500 16454 16448>,
			<17200 16779 16626 16506 16460 16449>,
			<17193 16831 16646 16512 16466 16452>,
			<17167 16919 16673 16519 16473 16456>,
			<17127 16935 16702 16528 16479 16461>,
			<17018 16906 16736 16543 16483 16469>,
			<16919 16870 16754 16559 16489 16479>,
			<16888 16841 16747 16586 16504 16489>,
			<16868 16807 16729 16610 16523 16499>,
			<16841 16770 16701 16611 16533 16508>,
			<16798 16724 16642 16599 16540 16516>,
			<16764 16683 16593 16582 16543 16520>,
			<16750 16655 16568 16537 16512 16496>,
			<16739 16632 16551 16488 16464 16455>,
			<16737 16612 16544 16481 16454 16446>,
			<16747 16592 16539 16482 16456 16447>,
			<16756 16579 16537 16482 16459 16448>,
			<16756 16574 16536 16486 16465 16453>,
			<16755 16571 16536 16494 16475 16462>,
			<16754 16570 16536 16501 16485 16471>,
			<16754 16574 16533 16508 16496 16480>,
			<16755 16579 16529 16516 16506 16490>,
			<16758 16582 16522 16527 16515 16501>,
			<16762 16587 16512 16537 16523 16510>,
			<16765 16595 16512 16542 16523 16510>,
			<16767 16613 16525 16545 16517 16498>,
			<16768 16635 16542 16545 16508 16485>,
			<16768 16659 16563 16527 16493 16475>,
			<16765 16686 16587 16504 16477 16467>,
			<16762 16702 16600 16500 16474 16465>,
			<16760 16713 16609 16499 16474 16464>,
			<16759 16719 16614 16499 16473 16464>,
			<16761 16709 16617 16502 16472 16462>,
			<16773 16687 16619 16503 16468 16457>,
			<16786 16673 16606 16493 16453 16444>,
			<16805 16670 16603 16492 16449 16442>,
			<16864 16673 16591 16491 16457 16449>,
			<16846 16683 16608 16503 16465 16451>,
			<16921 16710 16638 16518 16475 16464>,
			<17056 16745 16685 16538 16499 16513>,
			<17284 16783 16730 16552 16528 16524>,
			<17714 16862 16734 16531 16465 16454>,
			<18800 17209 16734 16517 16453 16446>,
			<24209 19017 16785 16541 16461 16453>,
			<65535 37216 17380 16591 16490 16479>,
			<65535 37216 17380 16591 16490 16479>,
			<65535 37216 17380 16591 16490 16479>;
	};

	qcom,pc-temp-y5-lut {
		qcom,lut-col-legend = <(-10) 0 10 25 40 50>;
		qcom,lut-row-legend = <10000 9800 9600 9400 9200 9000>,
			<8800 8600 8400 8200 8000 7800>,
			<7600 7400 7200 7000 6800 6600>,
			<6400 6200 6000 5800 5600 5400>,
			<5200 5000 4800 4600 4400 4200>,
			<4000 3800 3600 3400 3200 3000>,
			<2800 2600 2400 2200 2000 1800>,
			<1600 1400 1200 1000 900 800>,
			<700 600 500 400 300 200>,
			<100 0>;
		qcom,lut-data = <18408 17473 17352 14586 19288 20803>,
			<17194 18024 18001 15218 17905 20385>,
			<16655 18349 18432 15963 17066 19924>,
			<16637 18501 18672 16662 16634 19447>,
			<16987 18536 18746 17157 16474 18982>,
			<17552 18509 18680 17286 16452 18554>,
			<19068 18272 18430 17008 17480 18110>,
			<21084 17855 18021 16565 19084 17688>,
			<21186 17609 17555 16173 19289 17531>,
			<18596 17573 16947 15697 18591 17914>,
			<16593 17585 16314 15323 17759 18235>,
			<18550 17157 15589 15120 16856 18276>,
			<22405 16492 14948 15024 16033 18173>,
			<23349 16969 15012 14903 15943 17630>,
			<22024 20437 16251 14389 16237 16482>,
			<20895 22964 17932 14077 16430 15694>,
			<21308 23018 20409 14124 16016 15510>,
			<22284 23015 22993 14251 15359 15404>,
			<22565 23007 23469 15251 15550 15701>,
			<21118 22946 23329 18826 17402 17688>,
			<19318 22904 23114 20798 19103 19416>,
			<17163 23035 22679 20552 20021 19963>,
			<13729 23335 22143 20191 20708 20272>,
			<12448 23648 21987 20111 20675 20277>,
			<12225 24186 22030 20180 19689 20115>,
			<12127 24541 22145 20185 18627 19834>,
			<12188 21446 22378 20016 17792 18788>,
			<12393 15398 22719 19821 17120 17255>,
			<12583 13713 23059 19703 17028 16706>,
			<12731 13896 23570 19549 17170 16509>,
			<12881 14197 23860 19547 17407 16427>,
			<13052 14938 23002 19818 18433 16625>,
			<13244 16337 21516 20291 19852 17120>,
			<13453 17628 21182 21167 20140 17763>,
			<13783 18924 21292 22690 20014 18836>,
			<14084 19918 21390 23367 19922 19497>,
			<14170 19900 21291 23032 20108 19297>,
			<14211 18958 21016 22395 20401 18916>,
			<14220 18325 20731 21508 20198 18726>,
			<14008 16888 20228 20173 18705 18608>,
			<13637 15731 19646 19242 17659 18617>,
			<13281 15501 18867 18512 17677 19284>,
			<12925 15070 18238 18123 17880 20088>,
			<12935 14370 18410 18362 19933 19902>,
			<13139 13996 18039 18693 20150 18657>,
			<12887 14090 17899 18694 18146 17945>,
			<12947 13771 16562 17878 16997 19052>,
			<12577 14077 15867 17293 16629 21372>,
			<11999 14107 14410 18006 20123 21155>,
			<11401 14142 14292 19235 19864 18590>,
			<10681 13595 14314 19556 20769 22378>,
			<9787 11497 14388 21673 22792 24121>,
			<9117 9831 14016 22689 21899 24278>,
			<8822 9021 11438 23106 25798 26281>,
			<8822 9021 11438 23106 25798 26281>,
			<8822 9021 11438 23106 25798 26281>;
	};

	qcom,pc-temp-y6-lut {
		qcom,lut-col-legend = <(-10) 0 10 25 40 50>;
		qcom,lut-row-legend = <10000 9800 9600 9400 9200 9000>,
			<8800 8600 8400 8200 8000 7800>,
			<7600 7400 7200 7000 6800 6600>,
			<6400 6200 6000 5800 5600 5400>,
			<5200 5000 4800 4600 4400 4200>,
			<4000 3800 3600 3400 3200 3000>,
			<2800 2600 2400 2200 2000 1800>,
			<1600 1400 1200 1000 900 800>,
			<700 600 500 400 300 200>,
			<100 0>;
		qcom,lut-data = <5742 5319 5123 4993 4954 4943>,
			<5750 5324 5125 4994 4954 4944>,
			<5758 5329 5127 4995 4955 4944>,
			<5766 5335 5129 4997 4955 4945>,
			<5773 5339 5131 4998 4957 4946>,
			<5780 5342 5132 4999 4958 4947>,
			<5788 5342 5132 5001 4960 4948>,
			<5796 5342 5133 5002 4961 4949>,
			<5798 5342 5133 5004 4963 4951>,
			<5799 5342 5135 5006 4965 4953>,
			<5799 5342 5137 5008 4967 4954>,
			<5802 5351 5140 5010 4969 4956>,
			<5806 5364 5146 5013 4971 4959>,
			<5802 5367 5152 5017 4974 4961>,
			<5769 5365 5161 5020 4977 4963>,
			<5738 5361 5166 5024 4980 4965>,
			<5730 5352 5164 5031 4985 4969>,
			<5725 5336 5158 5037 4990 4973>,
			<5718 5321 5149 5037 4991 4975>,
			<5703 5305 5127 5034 4990 4976>,
			<5689 5291 5109 5028 4989 4976>,
			<5682 5283 5100 5012 4978 4966>,
			<5676 5277 5094 4995 4961 4950>,
			<5676 5274 5092 4992 4957 4947>,
			<5689 5271 5091 4993 4957 4947>,
			<5710 5269 5090 4993 4958 4948>,
			<5731 5264 5091 4995 4960 4949>,
			<5756 5259 5092 4997 4962 4952>,
			<5782 5259 5092 4999 4965 4954>,
			<5810 5269 5093 5002 4969 4957>,
			<5840 5283 5093 5004 4972 4960>,
			<5873 5299 5092 5008 4976 4963>,
			<5910 5320 5091 5011 4980 4967>,
			<5950 5343 5092 5014 4980 4967>,
			<5992 5370 5100 5016 4977 4963>,
			<6038 5400 5110 5016 4974 4959>,
			<6085 5432 5122 5011 4969 4956>,
			<6134 5466 5136 5004 4964 4953>,
			<6186 5499 5150 5004 4963 4952>,
			<6239 5534 5163 5004 4963 4953>,
			<6297 5571 5177 5004 4963 4953>,
			<6361 5610 5194 5007 4963 4953>,
			<6434 5655 5213 5008 4963 4953>,
			<6515 5710 5233 5006 4958 4947>,
			<6624 5787 5262 5009 4958 4946>,
			<6854 5865 5269 5010 4963 4952>,
			<6918 5912 5287 5016 4967 4956>,
			<7207 6012 5327 5024 4971 4961>,
			<7682 6147 5375 5035 4982 4977>,
			<8478 6342 5440 5043 4991 4979>,
			<9970 6769 5511 5035 4970 4957>,
			<13277 7857 5633 5034 4966 4956>,
			<23160 10979 5905 5052 4971 4959>,
			<65535 24949 6882 5079 4984 4970>,
			<65535 24949 6882 5079 4984 4970>,
			<65535 24949 6882 5079 4984 4970>;
	};

};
